# SERDES_10G0 register map
Vendor: Texas Instruments
Registers are 32-bit, access per field, reset 0x0 unless marked. A register's access mark holds for its fields unless they carry their own. Offsets are as the file gives them; [hi:lo] are bit positions; {n}, {i} and the like mark numbered series.

## SERDES_10G0 (part 5 of 8)
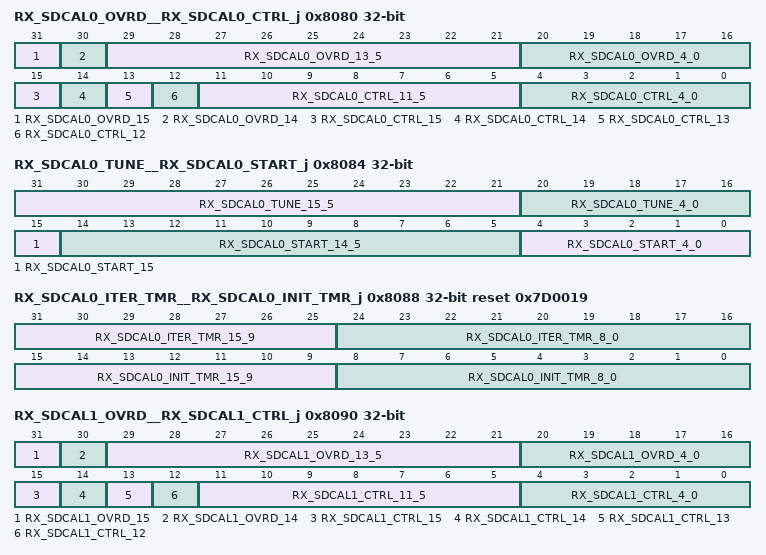
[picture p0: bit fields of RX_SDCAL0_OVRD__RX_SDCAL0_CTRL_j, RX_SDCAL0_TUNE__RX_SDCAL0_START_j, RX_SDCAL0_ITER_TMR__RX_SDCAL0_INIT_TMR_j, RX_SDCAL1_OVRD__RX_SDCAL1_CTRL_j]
0x8080 RX_SDCAL0_OVRD__RX_SDCAL0_CTRL_j — Signal detect calibration 0 control register Offset = 8080h + (j * 400h); where j = 0h to 3h
  [31] RX_SDCAL0_OVRD_15 rw — Calibration code override enable: Activation (1'b1) of this register bit allows the codes determined during the automatic calibration process to be overridden.
  [30] RX_SDCAL0_OVRD_14 rw — Analog calibration enable override: Activation (1'b1) of this register bit will force the analog calibration circuits to be enabled by activating the rxda_sd_cal_0_en enable and the rxda_sd_cal_0_clk clock.
  [29:21] RX_SDCAL0_OVRD_13_5 ro — Reserved
  [20:16] RX_SDCAL0_OVRD_4_0 rw — Calibration code override value: These bits are used to override the calibration code determined during the automatic calibration process.
  [15] RX_SDCAL0_CTRL_15 rw — Start calibration: Activating (1'b1) this bit will start the calibration process.
  [14] RX_SDCAL0_CTRL_14 ro — Calibration process done: This bit will be set to 1'b1 when the calibration process is complete.
  [13] RX_SDCAL0_CTRL_13 ro — No analog calibration response : This signal indicates that the calibration function has gone through the entire calibration process, reached the final calibration value, and the analog has not responded indicating that a valid calibration value has been reached.
  [12] RX_SDCAL0_CTRL_12 ro — Current analog comparator response: This is the current state of the analog comparator response signal (rxda_sd_cal_0_comp).
  [11:5] RX_SDCAL0_CTRL_11_5 ro — Reserved
  [4:0] RX_SDCAL0_CTRL_4_0 ro — Calibration code: This is the calibration code that was determined by the calibration process.
0x8084 RX_SDCAL0_TUNE__RX_SDCAL0_START_j — Signal detect calibration 0 start register Offset = 8084h + (j * 400h); where j = 0h to 3h
  [31:21] RX_SDCAL0_TUNE_15_5 ro — Reserved
  [20:16] RX_SDCAL0_TUNE_4_0 rw — Calibration tune value: The value of this field is added to the automatically calibrated code, or the override code if override is enabled.
  [15] RX_SDCAL0_START_15 rw — Calibration direction: This controls the direction that the automatic calibration process steps the calibration codes in.
  [14:5] RX_SDCAL0_START_14_5 ro — Reserved
  [4:0] RX_SDCAL0_START_4_0 rw — Start calibration code: This is the calibration code that the calibration process starts with when automatic calibration is run.
0x8088 RX_SDCAL0_ITER_TMR__RX_SDCAL0_INIT_TMR_j reset 0x7D0019 — Signal detect calibration 0 initialization timer register Offset = 8088h + (j * 400h); where j = 0h to 3h
  [31:25] RX_SDCAL0_ITER_TMR_15_9 ro — Reserved
  [24:16] RX_SDCAL0_ITER_TMR_8_0 rw — Iteration wait timer value: This is the number of cmn_ref_clk clocks to wait between when a value is placed on the calibration code signals going to the analog, and when the comparator value coming from the analog circuits can be checked.
  [15:9] RX_SDCAL0_INIT_TMR_15_9 ro — Reserved
  [8:0] RX_SDCAL0_INIT_TMR_8_0 rw — Initialization wait timer value: This is the number of cmn_ref_clk clocks to wait between when the analog calibration circuits are enabled, and when the first values are placed on the calibration code signals going to the analog.
0x8090 RX_SDCAL1_OVRD__RX_SDCAL1_CTRL_j — Signal detect calibration 1 control register Offset = 8090h + (j * 400h); where j = 0h to 3h
  [31] RX_SDCAL1_OVRD_15 rw — Calibration code override enable: Activation (1'b1) of this register bit allows the calibration code determined during the automatic calibration process to be overridden.
  [30] RX_SDCAL1_OVRD_14 rw — Analog calibration enable override: Activation (1'b1) of this register bit will force the analog calibration circuits to be enabled by activating the rxda_sd_cal_1_en enable and the rxda_sd_cal_1_clk clock.
  [29:21] RX_SDCAL1_OVRD_13_5 ro — Reserved
  [20:16] RX_SDCAL1_OVRD_4_0 rw — Calibration code override value: These bits are used to override the calibration code determined during the automatic calibration process.
  [15] RX_SDCAL1_CTRL_15 rw — Start calibration: Activating (1'b1) this bit will start the calibration process.
  [14] RX_SDCAL1_CTRL_14 ro — Calibration process done: This bit will be set to 1'b1 when the calibration process is complete.
  [13] RX_SDCAL1_CTRL_13 ro — No analog calibration response : This signal indicates that the calibration function has gone through the entire calibration process, reached the final calibration value, and the analog has not responded indicating that a valid calibration value has been reached.
  [12] RX_SDCAL1_CTRL_12 ro — Current analog comparator response: This is the current state of the analog comparator response signal (rxda_sd_cal_0_comp).
  [11:5] RX_SDCAL1_CTRL_11_5 ro — Reserved
  [4:0] RX_SDCAL1_CTRL_4_0 ro — Calibration code: This is the calibration code that was determined by the calibration process.
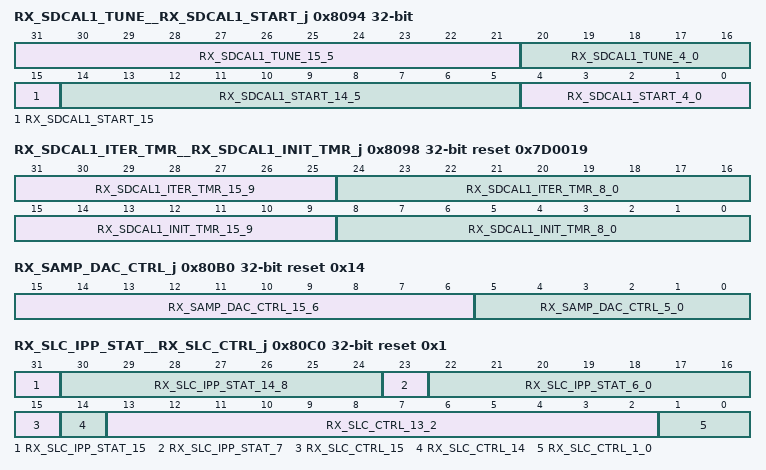
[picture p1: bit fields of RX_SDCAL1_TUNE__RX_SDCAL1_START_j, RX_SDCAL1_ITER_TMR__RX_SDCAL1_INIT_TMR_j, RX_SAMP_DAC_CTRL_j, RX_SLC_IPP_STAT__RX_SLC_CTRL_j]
0x8094 RX_SDCAL1_TUNE__RX_SDCAL1_START_j — Signal detect calibration 1 start register Offset = 8094h + (j * 400h); where j = 0h to 3h
  [31:21] RX_SDCAL1_TUNE_15_5 ro — Reserved
  [20:16] RX_SDCAL1_TUNE_4_0 rw — Calibration tune value: The value of this field is added to the automatically calibrated code, or the override code if override is enabled.
  [15] RX_SDCAL1_START_15 rw — Calibration direction: This controls the direction that the automatic calibration process steps the calibration codes in.
  [14:5] RX_SDCAL1_START_14_5 ro — Reserved
  [4:0] RX_SDCAL1_START_4_0 rw — Start calibration code: This is the calibration code that the calibration process starts with when automatic calibration is run.
0x8098 RX_SDCAL1_ITER_TMR__RX_SDCAL1_INIT_TMR_j reset 0x7D0019 — Signal detect calibration 1 initialization timer register Offset = 8098h + (j * 400h); where j = 0h to 3h
  [31:25] RX_SDCAL1_ITER_TMR_15_9 ro — Reserved
  [24:16] RX_SDCAL1_ITER_TMR_8_0 rw — Iteration wait timer value: This is the number of cmn_ref_clk clocks to wait between when a value is placed on the calibration code signals going to the analog, and when the comparator value coming from the analog circuits can be checked.
  [15:9] RX_SDCAL1_INIT_TMR_15_9 ro — Reserved
  [8:0] RX_SDCAL1_INIT_TMR_8_0 rw — Initialization wait timer value: This is the number of cmn_ref_clk clocks to wait between when the analog calibration circuits are enabled, and when the first values are placed on the calibration code signals going to the analog.
0x80B0 RX_SAMP_DAC_CTRL_j reset 0x14 — Sampler error DAC control register Offset = 80B0h + (j * 400h); where j = 0h to 3h
  [15:6] RX_SAMP_DAC_CTRL_15_6 ro — Reserved
  [5:0] RX_SAMP_DAC_CTRL_5_0 rw — Sampler error DAC value: Specifies the input value to the sampler error DAC.
0x80C0 RX_SLC_IPP_STAT__RX_SLC_CTRL_j reset 0x1 — RX sampler latch calibration control register Offset = 80C0h + (j * 400h); where j = 0h to 3h
  [31] RX_SLC_IPP_STAT_15 ro — Reserved
  [30:24] RX_SLC_IPP_STAT_14_8 ro — I even latch receiver sampler calibration DAC value: This field contains the current value that the RX sampler latch calibration module has calculated to drive to the DAC that controls the offset for the I even latch in the analog sampler component.
  [23] RX_SLC_IPP_STAT_7 ro — Reserved
  [22:16] RX_SLC_IPP_STAT_6_0 ro — I odd latch receiver sampler calibration DAC value: This field contains the current value that the RX sampler latch calibration module has calculated to drive to the DAC that controls the offset for the I odd latch in the analog sampler component.
  [15] RX_SLC_CTRL_15 rw — Start RX sampler latch calibration: Activating (1'b1) this bit will start the RX sampler latch calibration process.
  [14] RX_SLC_CTRL_14 ro — RX sampler latch calibration process done: This bit will be set to 1'b1 when the RX sampler latch calibration process is complete.
  [13:2] RX_SLC_CTRL_13_2 ro — Reserved
  [1:0] RX_SLC_CTRL_1_0 rw — RX sampler latch calibration scaler: This field specifies the scaler value used for the input data accumulator.
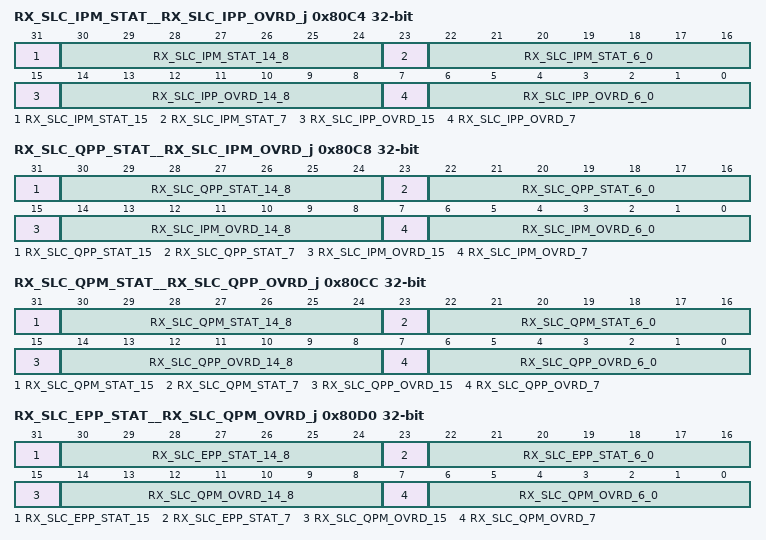
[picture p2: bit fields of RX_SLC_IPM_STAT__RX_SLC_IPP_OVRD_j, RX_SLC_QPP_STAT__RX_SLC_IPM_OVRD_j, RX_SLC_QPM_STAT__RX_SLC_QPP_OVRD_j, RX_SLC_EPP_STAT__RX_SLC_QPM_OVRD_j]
0x80C4 RX_SLC_IPM_STAT__RX_SLC_IPP_OVRD_j — RX sampler latch calibration I predictive positive override register Offset = 80C4h + (j * 400h); where j = 0h to 3h
  [31] RX_SLC_IPM_STAT_15 ro — Reserved
  [30:24] RX_SLC_IPM_STAT_14_8 ro — I even latch receiver sampler calibration DAC value: This field contains the current value that the RX sampler latch calibration module has calculated to drive to the DAC that controls the offset for the I even latch in the analog sampler component.
  [23] RX_SLC_IPM_STAT_7 ro — Reserved
  [22:16] RX_SLC_IPM_STAT_6_0 ro — I odd latch receiver sampler calibration DAC value: This field contains the current value that the RX sampler latch calibration module has calculated to drive to the DAC that controls the offset for the I odd latch in the analog sampler component.
  [15] RX_SLC_IPP_OVRD_15 rw — I even latch receiver sampler calibration DAC override enable: When this bit is active (1'b1), the value in the I even latch receiver sampler calibration DAC override value field of this register will override the calibrated value for the I even sampler latch.
  [14:8] RX_SLC_IPP_OVRD_14_8 rw — I even latch receiver sampler calibration DAC override value: This field contains the value that can be used to override the calibrated value for the I even sampler latch.
  [7] RX_SLC_IPP_OVRD_7 rw — I odd latch receiver sampler calibration DAC override enable: When this bit is active (1'b1), the value in the I odd latch receiver sampler calibration DAC override value field of this register will override the calibrated value for the I odd sampler latch.
  [6:0] RX_SLC_IPP_OVRD_6_0 rw — I odd latch receiver sampler calibration DAC override value: This field contains the value that can be used to override the calibrated value for the I odd sampler latch.
0x80C8 RX_SLC_QPP_STAT__RX_SLC_IPM_OVRD_j — RX sampler latch calibration I predictive negative override register Offset = 80C8h + (j * 400h); where j = 0h to 3h
  [31] RX_SLC_QPP_STAT_15 ro — Reserved
  [30:24] RX_SLC_QPP_STAT_14_8 ro — Q even latch receiver sampler calibration DAC value: This field contains the current value that the RX sampler latch calibration module has calculated to drive to the DAC that controls the offset for the Q even latch in the analog sampler component.
  [23] RX_SLC_QPP_STAT_7 ro — Reserved
  [22:16] RX_SLC_QPP_STAT_6_0 ro — Q odd latch receiver sampler calibration DAC value: This field contains the current value that the RX sampler latch calibration module has calculated to drive to the DAC that controls the offset for the Q odd latch in the analog sampler component.
  [15] RX_SLC_IPM_OVRD_15 rw — I eve latch receiver sampler calibration DAC override enable: When this bit is active (1'b1), the value in the I even latch receiver sampler calibration DAC override value field of this register will override the calibrated value for the I even sampler latch.
  [14:8] RX_SLC_IPM_OVRD_14_8 rw — I even latch receiver sampler calibration DAC override value: This field contains the value that can be used to override the calibrated value for the I even sampler latch.
  [7] RX_SLC_IPM_OVRD_7 rw — I odd latch receiver sampler calibration DAC override enable: When this bit is active (1'b1), the value in the I odd latch receiver sampler calibration DAC override value field of this register will override the calibrated value for the I odd sampler latch.
  [6:0] RX_SLC_IPM_OVRD_6_0 rw — I odd latch receiver sampler calibration DAC override value: This field contains the value that can be used to override the calibrated value for the I odd sampler latch.
0x80CC RX_SLC_QPM_STAT__RX_SLC_QPP_OVRD_j — RX sampler latch calibration Q predictive positive override register Offset = 80CCh + (j * 400h); where j = 0h to 3h
  [31] RX_SLC_QPM_STAT_15 ro — Reserved
  [30:24] RX_SLC_QPM_STAT_14_8 ro — Q even latch receiver sampler calibration DAC value: This field contains the current value that the RX sampler latch calibration module has calculated to drive to the DAC that controls the offset for the Q even latch in the analog sampler component.
  [23] RX_SLC_QPM_STAT_7 ro — Reserved
  [22:16] RX_SLC_QPM_STAT_6_0 ro — Q odd latch receiver sampler calibration DAC value: This field contains the current value that the RX sampler latch calibration module has calculated to drive to the DAC that controls the offset for the Q odd latch in the analog sampler component.
  [15] RX_SLC_QPP_OVRD_15 rw — Q even latch receiver sampler calibration DAC override enable: When this bit is active (1'b1), the value in the Q even latch receiver sampler calibration DAC override value field of this register will override the calibrated value for the Q even sampler latch.
  [14:8] RX_SLC_QPP_OVRD_14_8 rw — Q even latch receiver sampler calibration DAC override value: This field contains the value that can be used to override the calibrated value for the Q even sampler latch.
  [7] RX_SLC_QPP_OVRD_7 rw — Q odd latch receiver sampler calibration DAC override enable: When this bit is active (1'b1), the value in the Q odd latch receiver sampler calibration DAC override value field of this register will override the calibrated value for the Q odd sampler latch.
  [6:0] RX_SLC_QPP_OVRD_6_0 rw — Q odd latch receiver sampler calibration DAC override value: This field contains the value that can be used to override the calibrated value for the Q odd sampler latch.
0x80D0 RX_SLC_EPP_STAT__RX_SLC_QPM_OVRD_j — RX sampler latch calibration Q predictive negative override register Offset = 80D0h + (j * 400h); where j = 0h to 3h
  [31] RX_SLC_EPP_STAT_15 ro — Reserved
  [30:24] RX_SLC_EPP_STAT_14_8 ro — e even latch receiver sampler calibration DAC value: This field contains the current value that the RX sampler latch calibration module has calculated to drive to the DAC that controls the offset for the e even latch in the analog sampler component.
  [23] RX_SLC_EPP_STAT_7 ro — Reserved
  [22:16] RX_SLC_EPP_STAT_6_0 ro — e odd latch receiver sampler calibration DAC value: This field contains the current value that the RX sampler latch calibration module has calculated to drive to the DAC that controls the offset for the e odd latch in the analog sampler component.
  [15] RX_SLC_QPM_OVRD_15 rw — Q even latch receiver sampler calibration DAC override enable: When this bit is active (1'b1), the value in the Q even latch receiver sampler calibration DAC override value field of this register will override the calibrated value for the Q even sampler latch.
  [14:8] RX_SLC_QPM_OVRD_14_8 rw — Q even latch receiver sampler calibration DAC override value: This field contains the value that can be used to override the calibrated value for the Q even sampler latch.
  [7] RX_SLC_QPM_OVRD_7 rw — Q odd latch receiver sampler calibration DAC override enable: When this bit is active (1'b1), the value in the Q odd latch receiver sampler calibration DAC override value field of this register will override the calibrated value for the Q odd sampler latch.
  [6:0] RX_SLC_QPM_OVRD_6_0 rw — Q odd latch receiver sampler calibration DAC override value: This field contains the value that can be used to override the calibrated value for the Q odd sampler latch.
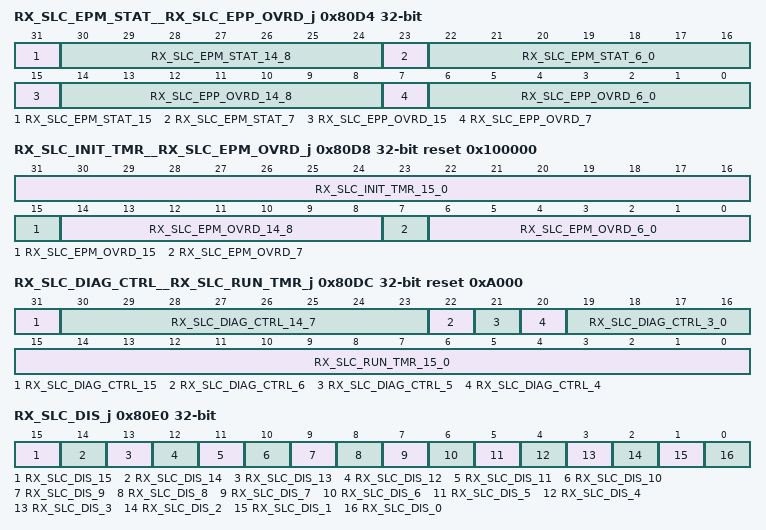
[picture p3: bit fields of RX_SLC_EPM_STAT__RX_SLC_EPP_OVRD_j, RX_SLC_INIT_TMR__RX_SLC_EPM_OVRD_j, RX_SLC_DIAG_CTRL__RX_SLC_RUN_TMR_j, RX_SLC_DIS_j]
0x80D4 RX_SLC_EPM_STAT__RX_SLC_EPP_OVRD_j — RX sampler latch calibration e predictive positive override register Offset = 80D4h + (j * 400h); where j = 0h to 3h
  [31] RX_SLC_EPM_STAT_15 ro — Reserved
  [30:24] RX_SLC_EPM_STAT_14_8 ro — e even latch receiver sampler calibration DAC value: This field contains the current value that the RX sampler latch calibration module has calculated to drive to the DAC that controls the offset for the e even latch in the analog sampler component.
  [23] RX_SLC_EPM_STAT_7 ro — Reserved
  [22:16] RX_SLC_EPM_STAT_6_0 ro — e odd latch receiver sampler calibration DAC value: This field contains the current value that the RX sampler latch calibration module has calculated to drive to the DAC that controls the offset for the e odd latch in the analog sampler component.
  [15] RX_SLC_EPP_OVRD_15 rw — e even latch receiver sampler calibration DAC override enable: When this bit is active (1'b1), the value in the e even latch receiver sampler calibration DAC override value field of this register will override the calibrated value for the e even sampler latch.
  [14:8] RX_SLC_EPP_OVRD_14_8 rw — e even latch receiver sampler calibration DAC override value: This field contains the value that can be used to override the calibrated value for the e even sampler latch.
  [7] RX_SLC_EPP_OVRD_7 rw — e odd latch receiver sampler calibration DAC override enable: When this bit is active (1'b1), the value in the e odd latch receiver sampler calibration DAC override value field of this register will override the calibrated value for the e odd sampler latch.
  [6:0] RX_SLC_EPP_OVRD_6_0 rw — e odd latch receiver sampler calibration DAC override value: This field contains the value that can be used to override the calibrated value for the e odd sampler latch.
0x80D8 RX_SLC_INIT_TMR__RX_SLC_EPM_OVRD_j rw reset 0x100000 — RX sampler latch calibration e predictive negative override register Offset = 80D8h + (j * 400h); where j = 0h to 3h
  [31:16] RX_SLC_INIT_TMR_15_0 — RX sampler latch calibration initialization timer value : This is the value that will be used for the RX sampler latch calibration initialization timer, which controls the time the rxda_sampler_latch_cal_en is held active prior to the individual calibration processes being kicked off.
  [15] RX_SLC_EPM_OVRD_15 — e even latch receiver sampler calibration DAC override enable: When this bit is active (1'b1), the value in the e even latch receiver sampler calibration DAC override value field of this register will override the calibrated value for the e even sampler latch.
  [14:8] RX_SLC_EPM_OVRD_14_8 — e even latch receiver sampler calibration DAC override value: This field contains the value that can be used to override the calibrated value for the e even sampler latch.
  [7] RX_SLC_EPM_OVRD_7 — e odd latch receiver sampler calibration DAC override enable: When this bit is active (1'b1), the value in the e odd latch receiver sampler calibration DAC override value field of this register will override the calibrated value for the e odd sampler latch.
  [6:0] RX_SLC_EPM_OVRD_6_0 — e odd latch receiver sampler calibration DAC override value: This field contains the value that can be used to override the calibrated value for the e odd sampler latch.
0x80DC RX_SLC_DIAG_CTRL__RX_SLC_RUN_TMR_j reset 0xA000 — RX sampler latch calibration run timer value register Offset = 80DCh + (j * 400h); where j = 0h to 3h
  [31] RX_SLC_DIAG_CTRL_15 rw — Diagnostic control enable : This bit enables the selected RX sampler latch calibration data sub module for diagnostic purposes.
  [30:23] RX_SLC_DIAG_CTRL_14_7 ro — Reserved
  [22] RX_SLC_DIAG_CTRL_6 rw — Voter override neg : When enabled using the voter override enable bit in this register, writing a 1'b1 in this register bit will force the voter in the selected RX sampler latch calibration data sub module to activate the voter neg signal for a single clock cycle.
  [21] RX_SLC_DIAG_CTRL_5 rw — Voter override pos : When enabled using the voter override enable bit in this register, writing a 1'b1 in this register bit will force the voter in the selected RX sampler latch calibration data sub module to activate the voter pos signal for a single clock cycle.
  [20] RX_SLC_DIAG_CTRL_4 rw — Voter override enable : Setting this bit to a 1'b1 will enable the voter override function in the selected RX sampler latch calibration data sub module.
  [19:16] RX_SLC_DIAG_CTRL_3_0 rw — Diagnostic control override select : Selects the RX sampler latch calibration data sub module to enable for diagnostic and verification purposes.
  [15:0] RX_SLC_RUN_TMR_15_0 rw — RX sampler latch calibration run timer value : This is the value that will be used for the RX sampler latch calibration run timer, which controls the run time for each calibration process.
0x80E0 RX_SLC_DIS_j — RX sampler latch calibration disable register Offset = 80E0h + (j * 400h); where j = 0h to 3h
  [15] RX_SLC_DIS_15 ro — Reserved
  [14] RX_SLC_DIS_14 rw — e even negative coefficient disable : Writing a 1'b1 to this bit will disable auto calibration for the e even negative coefficient RX sampler latch calibration data sub module.
  [13] RX_SLC_DIS_13 rw — q even negative coefficient disable : Writing a 1'b1 to this bit will disable auto calibration for the q even negative coefficient RX sampler latch calibration data sub module.
  [12] RX_SLC_DIS_12 rw — i even negative coefficient disable : Writing a 1'b1 to this bit will disable auto calibration for the i even negative coefficient RX sampler latch calibration data sub module.
  [11] RX_SLC_DIS_11 ro — Reserved
  [10] RX_SLC_DIS_10 rw — e even positive coefficient disable : Writing a 1'b1 to this bit will disable auto calibration for the e even positive coefficient RX sampler latch calibration data sub module.
  [9] RX_SLC_DIS_9 rw — q even positive coefficient disable : Writing a 1'b1 to this bit will disable auto calibration for the q even positive coefficient RX sampler latch calibration data sub module.
  [8] RX_SLC_DIS_8 rw — i even positive coefficient disable : Writing a 1'b1 to this bit will disable auto calibration for the i even positive coefficient RX sampler latch calibration data sub module.
  [7] RX_SLC_DIS_7 ro — Reserved
  [6] RX_SLC_DIS_6 rw — e odd negative coefficient disable : Writing a 1'b1 to this bit will disable auto calibration for the e odd negative coefficient RX sampler latch calibration data sub module.
  [5] RX_SLC_DIS_5 rw — q odd negative coefficient disable : Writing a 1'b1 to this bit will disable auto calibration for the q odd negative coefficient RX sampler latch calibration data sub module.
  [4] RX_SLC_DIS_4 rw — i odd negative coefficient disable : Writing a 1'b1 to this bit will disable auto calibration for the i odd negative coefficient RX sampler latch calibration data sub module.
  [3] RX_SLC_DIS_3 ro — Reserved
  [2] RX_SLC_DIS_2 rw — e odd positive coefficient disable : Writing a 1'b1 to this bit will disable auto calibration for the e odd positive coefficient RX sampler latch calibration data sub module.
  [1] RX_SLC_DIS_1 rw — q odd positive coefficient disable : Writing a 1'b1 to this bit will disable auto calibration for the q odd positive coefficient RX sampler latch calibration data sub module.
  [0] RX_SLC_DIS_0 rw — i odd positive coefficient disable : Writing a 1'b1 to this bit will disable auto calibration for the i odd positive coefficient RX sampler latch calibration data sub module.
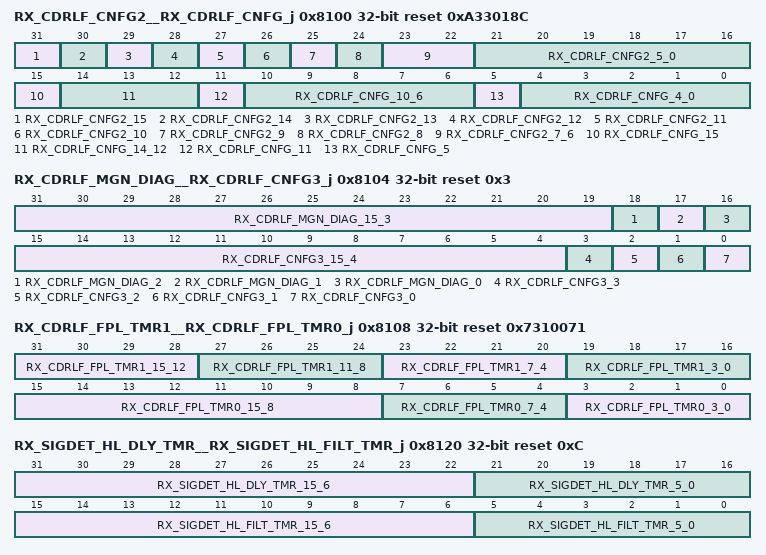
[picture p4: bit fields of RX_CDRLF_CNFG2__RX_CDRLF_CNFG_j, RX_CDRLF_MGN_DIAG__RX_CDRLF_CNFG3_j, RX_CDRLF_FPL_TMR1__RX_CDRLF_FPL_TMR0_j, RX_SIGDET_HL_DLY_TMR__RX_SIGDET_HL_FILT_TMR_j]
0x8100 RX_CDRLF_CNFG2__RX_CDRLF_CNFG_j reset 0xA33018C — CDRLF configuration register Offset = 8100h + (j * 400h); where j = 0h to 3h
  [31] RX_CDRLF_CNFG2_15 ro — Reserved
  [30] RX_CDRLF_CNFG2_14 rw — CDRLF second order loop integrator max clear enable: This signal enables the function in the CDRLF where the second order loop integrator is cleared when it reaches the maximum value.
  [29] RX_CDRLF_CNFG2_13 ro — CDRLF fast phase lock locked detected: This register bit is the current status of the fphl_locked pin on the CDRLF, and indicates the fast phase lock process is complete.
  [28] RX_CDRLF_CNFG2_12 rw — CDRLF fast phase lock diagnostic enable: This register bit can control the fphl_start pin on the CDRLF.
  [27] RX_CDRLF_CNFG2_11 rw — CDRLF fast phase lock enabled by signal detect: When active, signal detect will control the fphl_start pin on the CDRLF.
  [26] RX_CDRLF_CNFG2_10 rw — CDRLF reset on CDRLF PM Accumulator Max: Activating (1'b1) this bit will force the CDRLF to be reset when the PM accumulator in the CDRLF reaches is maximum absolute value (the largest positive or negative value).
  [25] RX_CDRLF_CNFG2_9 rw — CDRLF freeze on electrical idle detect: Activating (1'b1) this bit will force the CDRLF to be freeze in its current state when the receiver signal detect detects an electrical idle.
  [24] RX_CDRLF_CNFG2_8 rw — CDRLF reset on electrical idle detect: Activating (1'b1) this bit will force the CDRLF to be reset when the receiver signal detect detects an electrical idle.
  [23:22] RX_CDRLF_CNFG2_7_6 ro — Reserved
  [21:16] RX_CDRLF_CNFG2_5_0 rw — CDRLF second order loop integrator threshold : This value is the maximum magnitude the CDRLF second order loop integrator will be allowed to go to.
  [15] RX_CDRLF_CNFG_15 rw — CDLRF reset hold: When active (1'b1), the CDRLF will be held in reset beyond the time that it would normally be released by its asynchronous release signals.
  [14:12] RX_CDRLF_CNFG_14_12 rw — CDRLF diagnostic mode control: This field controls the information driven on the rx_pi_val_ln_{15:0}[7:0] signal, when in diagnostics mode.
  [11] RX_CDRLF_CNFG_11 rw — CDRLF second order loop disable: Activating (1'b1) this bit will disable the CDRLF second order loop.
  [10:6] RX_CDRLF_CNFG_10_6 rw — CDRLF second order loop sigma delta update rate: This is the value that is added to or subtracted from the second order loop accumulator register when the serial data sample clock is detected as being out of phase with the serial data on a given parallel data word cycle.
  [5] RX_CDRLF_CNFG_5 rw — CDRLF first order loop disable: Activating (1'b1) this bit will disable the CDRLF first order loop.
  [4:0] RX_CDRLF_CNFG_4_0 rw — CDRLF first order loop sigma delta update rate: This is the value that is added to or subtracted from the first order loop accumulator register when the serial data sample clock is detected as being out of phase with the serial data on a given parallel data word cycle.
0x8104 RX_CDRLF_MGN_DIAG__RX_CDRLF_CNFG3_j reset 0x3 — CDRLF configuration register 3 Offset = 8104h + (j * 400h); where j = 0h to 3h
  [31:19] RX_CDRLF_MGN_DIAG_15_3 ro — Reserved
  [18] RX_CDRLF_MGN_DIAG_2 wo — CDRLF PI override down : When the CDRLF PI override enable function is enabled, writing a 1'b1 to this bit will force a down to be generated in the CDRLF PI interface logic.
  [17] RX_CDRLF_MGN_DIAG_1 wo — CDRLF PI override up : When the CDRLF PI override enable function is enabled, writing a 1'b1 to this bit will force an up to be generated in the CDRLF PI interface logic.
  [16] RX_CDRLF_MGN_DIAG_0 rw — CDRLF PI override enable : Setting this bit to 1'b1 will enable the CDRLF PI override function, which will allow ups and downs to be forced to the CDRLF PI interface logic from the up and down override bits in this register.
  [15:4] RX_CDRLF_CNFG3_15_4 ro — Reserved
  [3] RX_CDRLF_CNFG3_3 rw — CDRLF data filter enable standard mode 3 : Enables the filter function for the data that feeds into the CDRLF from the deserializer, using the rxda_cdrlf_data_filter_en_n signal, when xcvr_standard_mode is set to 2'b11.
  [2] RX_CDRLF_CNFG3_2 rw — CDRLF data filter enable standard mode 2 : Enables the filter function for the data that feeds into the CDRLF from the deserializer, using the rxda_cdrlf_data_filter_en_n signal, when xcvr_standard_mode is set to 2'b10.
  [1] RX_CDRLF_CNFG3_1 rw — CDRLF data filter enable standard mode 1 : Enables the filter function for the data that feeds into the CDRLF from the deserializer, using the rxda_cdrlf_data_filter_en_n signal, when xcvr_standard_mode is set to 2'b01.
  [0] RX_CDRLF_CNFG3_0 rw — CDRLF data filter enable standard mode 0 : Enables the filter function for the data that feeds into the CDRLF from the deserializer, using the rxda_cdrlf_data_filter_en_n signal, when xcvr_standard_mode is set to 2'b00.
0x8108 RX_CDRLF_FPL_TMR1__RX_CDRLF_FPL_TMR0_j reset 0x7310071 — CDRLF fast phase lock timer value register 0 Offset = 8108h + (j * 400h); where j = 0h to 3h
  [31:28] RX_CDRLF_FPL_TMR1_15_12 ro — Reserved
  [27:24] RX_CDRLF_FPL_TMR1_11_8 rw — Fast phase lock timer trigger 1 state time value : Specifies the number of clock cycles minus 1 that the fast phase lock state machine will remain in the trigger state the first time it is in that state.
  [23:20] RX_CDRLF_FPL_TMR1_7_4 rw — Fast phase lock timer trigger 2 state time value : Specifies the number of clock cycles minus 1 that the fast phase lock state machine will remain in the trigger state the second time it is in that state.
  [19:16] RX_CDRLF_FPL_TMR1_3_0 rw — Fast phase lock timer trigger 3 state time value : Specifies the number of clock cycles minus 1 that the fast phase lock state machine will remain in the trigger state the third time it is in that state.
  [15:8] RX_CDRLF_FPL_TMR0_15_8 ro — Reserved
  [7:4] RX_CDRLF_FPL_TMR0_7_4 rw — Fast phase lock timer accumulate state time value : Specifies the number of clock cycles minus 1 that the fast phase lock state machine will remain in the accumulate state.
  [3:0] RX_CDRLF_FPL_TMR0_3_0 rw — Fast phase lock timer delay state time value : Specifies the number of clock cycles minus 1 that the fast phase lock state machine will remain in the delay state.
0x8120 RX_SIGDET_HL_DLY_TMR__RX_SIGDET_HL_FILT_TMR_j reset 0xC — Receiver signal detect filter high to low filter timer register Offset = 8120h + (j * 400h); where j = 0h to 3h
  [31:22] RX_SIGDET_HL_DLY_TMR_15_6 ro — Reserved
  [21:16] RX_SIGDET_HL_DLY_TMR_5_0 rw — Signal detect filter high to low delay timer value: This is the value loaded into the delay timer in the signal detect high to low filter circuit.
  [15:6] RX_SIGDET_HL_FILT_TMR_15_6 ro — Reserved
  [5:0] RX_SIGDET_HL_FILT_TMR_5_0 rw — Signal detect filter high to low filter timer value: This is the value loaded into the filter timer in the signal detect high to low filter circuit.
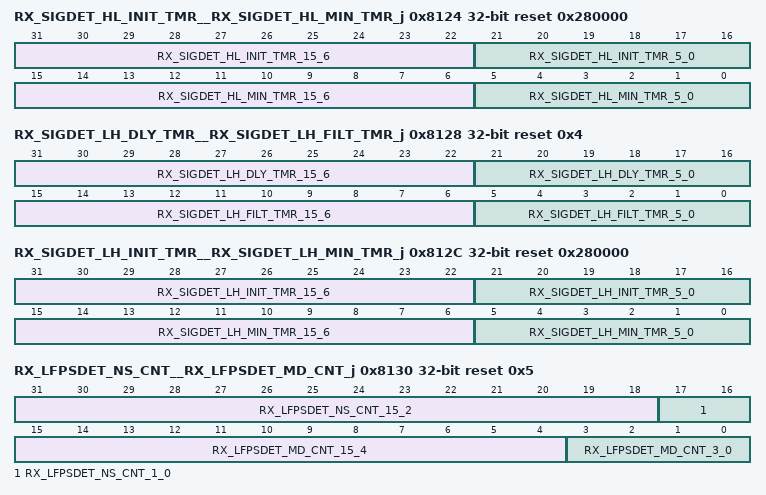
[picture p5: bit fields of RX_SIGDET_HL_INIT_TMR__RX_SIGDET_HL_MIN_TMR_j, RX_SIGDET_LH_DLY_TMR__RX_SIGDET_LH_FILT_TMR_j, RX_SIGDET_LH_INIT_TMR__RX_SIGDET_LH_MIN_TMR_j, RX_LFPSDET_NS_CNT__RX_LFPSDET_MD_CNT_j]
0x8124 RX_SIGDET_HL_INIT_TMR__RX_SIGDET_HL_MIN_TMR_j reset 0x280000 — Receiver signal detect filter high to low min timer register Offset = 8124h + (j * 400h); where j = 0h to 3h
  [31:22] RX_SIGDET_HL_INIT_TMR_15_6 ro — Reserved
  [21:16] RX_SIGDET_HL_INIT_TMR_5_0 rw — Signal detect init timer value: This is the value loaded into the initialization timer in the signal detect filter high to low filter circuit.
  [15:6] RX_SIGDET_HL_MIN_TMR_15_6 ro — Reserved
  [5:0] RX_SIGDET_HL_MIN_TMR_5_0 rw — Signal detect filter high to low min timer value: This is the value loaded into the min timer in the signal detect high to low filter circuit.
0x8128 RX_SIGDET_LH_DLY_TMR__RX_SIGDET_LH_FILT_TMR_j reset 0x4 — Receiver signal detect filter low to high filter timer register Offset = 8128h + (j * 400h); where j = 0h to 3h
  [31:22] RX_SIGDET_LH_DLY_TMR_15_6 ro — Reserved
  [21:16] RX_SIGDET_LH_DLY_TMR_5_0 rw — Signal detect filter low to high min timer value: This is the value loaded into the min timer in the signal detect low to high filter circuit.
  [15:6] RX_SIGDET_LH_FILT_TMR_15_6 ro — Reserved
  [5:0] RX_SIGDET_LH_FILT_TMR_5_0 rw — Signal detect filter low to high filter timer value: This is the value loaded into the filter timer in the signal detect low to high filter circuit.
0x812C RX_SIGDET_LH_INIT_TMR__RX_SIGDET_LH_MIN_TMR_j reset 0x280000 — Receiver signal detect filter low to high min timer register Offset = 812Ch + (j * 400h); where j = 0h to 3h
  [31:22] RX_SIGDET_LH_INIT_TMR_15_6 ro — Reserved
  [21:16] RX_SIGDET_LH_INIT_TMR_5_0 rw — Signal detect init timer value: This is the value loaded into the initialization timer in the signal detect filter high to low filter circuit.
  [15:6] RX_SIGDET_LH_MIN_TMR_15_6 ro — Reserved
  [5:0] RX_SIGDET_LH_MIN_TMR_5_0 rw — Signal detect filter high to low min timer value: This is the value loaded into the min timer in the signal detect high to low filter circuit.
0x8130 RX_LFPSDET_NS_CNT__RX_LFPSDET_MD_CNT_j reset 0x5 — Receiver LFPS detect minimum pulse distance counter register Offset = 8130h + (j * 400h); where j = 0h to 3h
  [31:18] RX_LFPSDET_NS_CNT_15_2 ro — Reserved
  [17:16] RX_LFPSDET_NS_CNT_1_0 rw — No signal counter value (NS): Specifies the number of clock cycles where pulse_high and pulse_low are inactive before declaring no signal.
  [15:4] RX_LFPSDET_MD_CNT_15_4 ro — Reserved
  [3:0] RX_LFPSDET_MD_CNT_3_0 rw — Minimum pulse distance counter value (MD): Specifies the minimum pulse distance for a valid LFPS sequence.
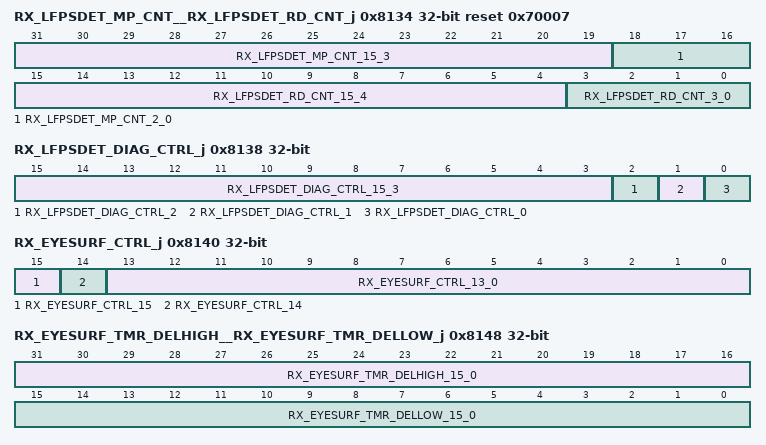
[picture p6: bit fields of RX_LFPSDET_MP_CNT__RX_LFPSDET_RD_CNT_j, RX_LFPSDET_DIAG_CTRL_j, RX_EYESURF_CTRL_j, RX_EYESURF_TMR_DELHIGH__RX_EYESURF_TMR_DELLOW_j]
0x8134 RX_LFPSDET_MP_CNT__RX_LFPSDET_RD_CNT_j reset 0x70007 — Receiver LFPS detect ramp down counter register Offset = 8134h + (j * 400h); where j = 0h to 3h
  [31:19] RX_LFPSDET_MP_CNT_15_3 ro — Reserved
  [18:16] RX_LFPSDET_MP_CNT_2_0 rw — Minimum pulse duration (MP): Specifies the minimum number of clock cycles required for a given LFPS pulse to be driven active to be considered part of a valid LFPS burst.
  [15:4] RX_LFPSDET_RD_CNT_15_4 ro — Reserved
  [3:0] RX_LFPSDET_RD_CNT_3_0 rw — Ramp down counter value (RD): Species the number of clock cycles that are used in the LFPS detect ramp down process.
0x8138 RX_LFPSDET_DIAG_CTRL_j — Receiver LFPS detect diagnostic control register Offset = 8138h + (j * 400h); where j = 0h to 3h
  [15:3] RX_LFPSDET_DIAG_CTRL_15_3 ro — Reserved
  [2] RX_LFPSDET_DIAG_CTRL_2 rw — Disable pulse none MD check: When active (1'b1), the check that tests if pulse_none is driven inactive while the MD check is being performed will be disabled.
  [1] RX_LFPSDET_DIAG_CTRL_1 rw — LFPS detect override enable: When active (1'b1), the LFPS detect override bit in this register will drive the LFPS detect output directly.
  [0] RX_LFPSDET_DIAG_CTRL_0 rw — LFPS detect override: When enabled by the LFPS detect override enable bit in this register, this bit will drive the LFPS detect output directly.
0x8140 RX_EYESURF_CTRL_j — Eye surf control register Offset = 8140h + (j * 400h); where j = 0h to 3h
  [15] RX_EYESURF_CTRL_15 rw — Eye surf run: Setting this bit to 1'b1 will initiate the eye surf process.
  [14] RX_EYESURF_CTRL_14 ro — Eye surf done: When this bit is set to 1'b1, the eye surf process has completed.
  [13:0] RX_EYESURF_CTRL_13_0 ro — Reserved
0x8148 RX_EYESURF_TMR_DELHIGH__RX_EYESURF_TMR_DELLOW_j rw — Eye surf timer delay low register Offset = 8148h + (j * 400h); where j = 0h to 3h
  [31:16] RX_EYESURF_TMR_DELHIGH_15_0 — Most significant 16 bits of the delay time: The delay time specifies the number of clock cycles to wait between when a coordinate test point is set, and when to start testing the i and e data.
  [15:0] RX_EYESURF_TMR_DELLOW_15_0 — Least significant 16 bits of the delay time: The delay time specifies the number of clock cycles to wait between when a coordinate test point is set, and when to start testing the i and e data.
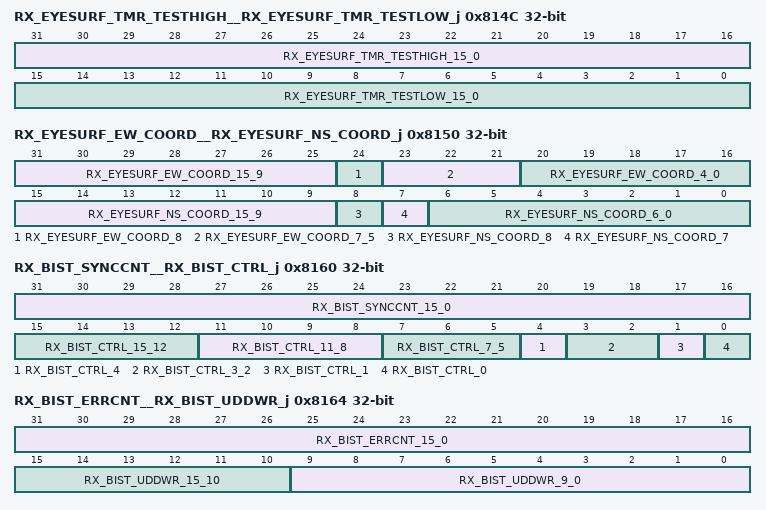
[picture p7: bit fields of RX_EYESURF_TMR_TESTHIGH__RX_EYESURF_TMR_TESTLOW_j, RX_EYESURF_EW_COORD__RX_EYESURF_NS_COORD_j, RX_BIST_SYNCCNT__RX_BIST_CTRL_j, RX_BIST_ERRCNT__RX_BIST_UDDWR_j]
0x814C RX_EYESURF_TMR_TESTHIGH__RX_EYESURF_TMR_TESTLOW_j rw — Eye surf timer test low register Offset = 814Ch + (j * 400h); where j = 0h to 3h
  [31:16] RX_EYESURF_TMR_TESTHIGH_15_0 — Most significant 16 bits of the test time: The test time specifies the number of clock cycles to test the i and e data at a given coordinate test point.
  [15:0] RX_EYESURF_TMR_TESTLOW_15_0 — Least significant 16 bits of the test time: The test time specifies the number of clock cycles to test the i and e data at a given coordinate test point.
0x8150 RX_EYESURF_EW_COORD__RX_EYESURF_NS_COORD_j — Eye surf north south test point coordinate register Offset = 8150h + (j * 400h); where j = 0h to 3h
  [31:25] RX_EYESURF_EW_COORD_15_9 ro — Reserved
  [24] RX_EYESURF_EW_COORD_8 rw — Test point coordinate east west direction : Indicates whether the desired test point is in the
  [23:21] RX_EYESURF_EW_COORD_7_5 ro — Reserved
  [20:16] RX_EYESURF_EW_COORD_4_0 rw — Test point coordinate east west offset : Indicates how many steps in the east or west
  [15:9] RX_EYESURF_NS_COORD_15_9 ro — Reserved
  [8] RX_EYESURF_NS_COORD_8 rw — Test point coordinate north south direction : Indicates whether the desired test point is in the north or the south direction relative to the origin.
  [7] RX_EYESURF_NS_COORD_7 ro — Reserved
  [6:0] RX_EYESURF_NS_COORD_6_0 rw — Test point coordinate north south offset : Indicates how many steps in the north or south direction the desired test point is relative to the origin.
0x8154 RX_EYESURF_ERRCNT_j ro — Eye surf bit error count register Offset = 8154h + (j * 400h); where j = 0h to 3h
  [15:0] RX_EYESURF_ERRCNT_15_0 — Test point bit error count : The total number of bit errors that were detected for a given run of the eye surf function.
0x8160 RX_BIST_SYNCCNT__RX_BIST_CTRL_j — Receiver BIST control register Offset = 8160h + (j * 400h); where j = 0h to 3h
  [31:16] RX_BIST_SYNCCNT_15_0 rw — Receiver BIST sync count: This field controls the value of the RX BIST sync count.
  [15:12] RX_BIST_CTRL_15_12 ro — Reserved
  [11:8] RX_BIST_CTRL_11_8 rw — Receiver BIST mode: Controls which mode the BIST will operate in.
  [7:5] RX_BIST_CTRL_7_5 ro — Reserved
  [4] RX_BIST_CTRL_4 rw — Receiver BIST error reset: Writing this bit is set to a 1'b1 will hold the error indicators in the receive BIST logic in reset.
  [3:2] RX_BIST_CTRL_3_2 ro — Reserved
  [1] RX_BIST_CTRL_1 wo — Receiver BIST user defined data FIFO clear: Writing a 1'b1 to this bit will clear the receiver BIST user defined data FIFO.
  [0] RX_BIST_CTRL_0 rw — Receiver BIST enable: This bit enables the receiver BIST function.
0x8164 RX_BIST_ERRCNT__RX_BIST_UDDWR_j — Receiver BIST user defined data write register Offset = 8164h + (j * 400h); where j = 0h to 3h
  [31:16] RX_BIST_ERRCNT_15_0 ro — Receiver BIST error count: Indicates the number of BIST errors that have been observed by the receive BIST logic, since the last time the BIST error indicator logic was reset or restarted.
  [15:10] RX_BIST_UDDWR_15_10 ro — Reserved
  [9:0] RX_BIST_UDDWR_9_0 wo — Receiver BIST user defined data: Writing a data word to this field will result in that data word being placed in the next available position in the receiver BIST user defined data FIFO.
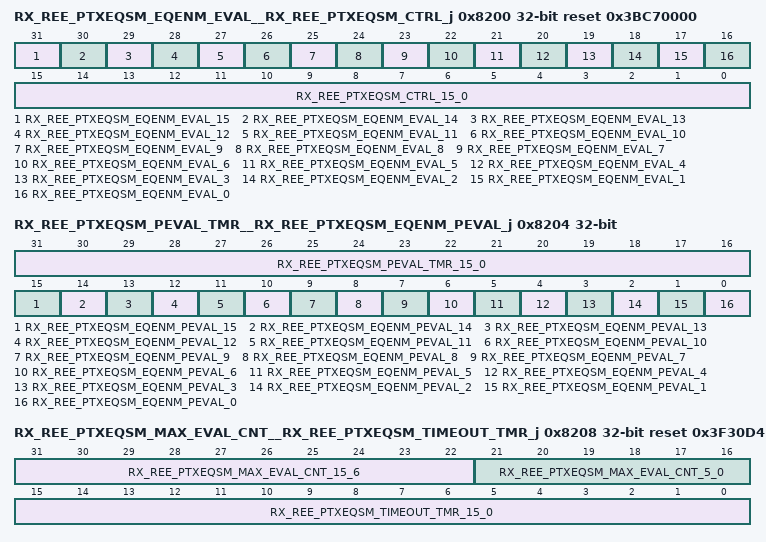
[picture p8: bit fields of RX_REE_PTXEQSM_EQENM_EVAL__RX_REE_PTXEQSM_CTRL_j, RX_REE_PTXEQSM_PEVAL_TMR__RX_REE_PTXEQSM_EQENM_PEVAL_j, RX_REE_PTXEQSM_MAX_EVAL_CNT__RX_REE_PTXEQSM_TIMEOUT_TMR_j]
0x8200 RX_REE_PTXEQSM_EQENM_EVAL__RX_REE_PTXEQSM_CTRL_j reset 0x3BC70000 — REE PCIe TX equalization control state machine control register Offset = 8200h + (j * 400h); where j = 0h to 3h
  [31] RX_REE_PTXEQSM_EQENM_EVAL_15 rw — Reserved - spare
  [30] RX_REE_PTXEQSM_EQENM_EVAL_14 rw — Ignore 1010 controller : When set to 1'b1, this function is enabled when the PCIe TX equalization control state machine is controlling the REE.
  [29] RX_REE_PTXEQSM_EQENM_EVAL_13 rw — TX equalization evaluator : When set to 1'b1, this function is enabled when the PCIe TX equalization control state machine is controlling the REE.
  [28] RX_REE_PTXEQSM_EQENM_EVAL_12 rw — TX post cursor control : When set to 1'b1, this function is enabled when the PCIe TX equalization control state machine is controlling the REE.
  [27] RX_REE_PTXEQSM_EQENM_EVAL_11 rw — TX pre cursor control : When set to 1'b1, this function is enabled when the PCIe TX equalization control state machine is controlling the REE.
  [26] RX_REE_PTXEQSM_EQENM_EVAL_10 rw — Short channel correction : When set to 1'b1, this function is enabled when the TX equalization general control state machine is controlling the REE.
  [25] RX_REE_PTXEQSM_EQENM_EVAL_9 rw — RX attenuation : When set to 1'b1, this function is enabled when the PCIe TX equalization control state machine is controlling the REE.
  [24] RX_REE_PTXEQSM_EQENM_EVAL_8 rw — RX VGA gain : When set to 1'b1, this function is enabled when the PCIe TX equalization control state machine is controlling the REE.
  [23] RX_REE_PTXEQSM_EQENM_EVAL_7 rw — RX offset correction coefficient : When set to 1'b1, this function is enabled when the PCIe TX equalization control state machine is controlling the REE.
  [22] RX_REE_PTXEQSM_EQENM_EVAL_6 rw — RX peaking amp gain : When set to 1'b1, this function is enabled when the PCIe TX equalization control state machine is controlling the REE.
  [21] RX_REE_PTXEQSM_EQENM_EVAL_5 rw — RX low frequency equalizer adaptive control : When set to 1'b1, this function is enabled when the PCIe TX equalization control state machine is controlling the REE.
  [20] RX_REE_PTXEQSM_EQENM_EVAL_4 rw — Reserved - spare
  [19] RX_REE_PTXEQSM_EQENM_EVAL_3 rw — Reserved - spare
  [18] RX_REE_PTXEQSM_EQENM_EVAL_2 rw — RX tap3 : When set to 1'b1, this function is enabled when the PCIe TX equalization control state machine is controlling the REE.
  [17] RX_REE_PTXEQSM_EQENM_EVAL_1 rw — RX tap2 : When set to 1'b1, this function is enabled when the PCIe TX equalization control state machine is controlling the REE.
  [16] RX_REE_PTXEQSM_EQENM_EVAL_0 rw — RX tap1 : When set to 1'b1, this function is enabled when the PCIe TX equalization control state machine is controlling the REE.
  [15:0] RX_REE_PTXEQSM_CTRL_15_0 ro — Reserved
0x8204 RX_REE_PTXEQSM_PEVAL_TMR__RX_REE_PTXEQSM_EQENM_PEVAL_j rw — REE PCIe TX equalization control state machine equalization enable mask for PCIe post evaluation equalization register Offset = 8204h + (j * 400h); where j = 0h to 3h
  [31:16] RX_REE_PTXEQSM_PEVAL_TMR_15_0 — Run post evaluation equalization timer value : This specifies number of clock cycles the state machine will wait in the Post Evaluation Equalization state.
  [15] RX_REE_PTXEQSM_EQENM_PEVAL_15 — Reserved - spare
  [14] RX_REE_PTXEQSM_EQENM_PEVAL_14 — Ignore 1010 controller : When set to 1'b1, this function is enabled when the PCIe TX equalization control state machine is controlling the REE.
  [13] RX_REE_PTXEQSM_EQENM_PEVAL_13 — TX equalization evaluator : When set to 1'b1, this function is enabled when the PCIe TX equalization control state machine is controlling the REE.
  [12] RX_REE_PTXEQSM_EQENM_PEVAL_12 — TX post cursor control : When set to 1'b1, this function is enabled when the PCIe TX equalization control state machine is controlling the REE.
  [11] RX_REE_PTXEQSM_EQENM_PEVAL_11 — TX pre cursor control : When set to 1'b1, this function is enabled when the PCIe TX equalization control state machine is controlling the REE.
  [10] RX_REE_PTXEQSM_EQENM_PEVAL_10 — Short channel correction : When set to 1'b1, this function is enabled when the TX equalization general control state machine is controlling the REE.
  [9] RX_REE_PTXEQSM_EQENM_PEVAL_9 — RX attenuation : When set to 1'b1, this function is enabled when the PCIe TX equalization control state machine is controlling the REE.
  [8] RX_REE_PTXEQSM_EQENM_PEVAL_8 — RX VGA gain : When set to 1'b1, this function is enabled when the PCIe TX equalization control state machine is controlling the REE.
  [7] RX_REE_PTXEQSM_EQENM_PEVAL_7 — RX offset correction coefficient : When set to 1'b1, this function is enabled when the PCIe TX equalization control state machine is controlling the REE.
  [6] RX_REE_PTXEQSM_EQENM_PEVAL_6 — RX peaking amp gain : When set to 1'b1, this function is enabled when the PCIe TX equalization control state machine is controlling the REE.
  [5] RX_REE_PTXEQSM_EQENM_PEVAL_5 — RX low frequency equalizer adaptive control : When set to 1'b1, this function is enabled when the PCIe TX equalization control state machine is controlling the REE.
  [4] RX_REE_PTXEQSM_EQENM_PEVAL_4 — Reserved - spare
  [3] RX_REE_PTXEQSM_EQENM_PEVAL_3 — Reserved - spare
  [2] RX_REE_PTXEQSM_EQENM_PEVAL_2 — RX tap 3 : When set to 1'b1, this function is enabled when the PCIe TX equalization control state machine is controlling the REE.
  [1] RX_REE_PTXEQSM_EQENM_PEVAL_1 — RX tap 2 : When set to 1'b1, this function is enabled when the PCIe TX equalization control state machine is controlling the REE.
  [0] RX_REE_PTXEQSM_EQENM_PEVAL_0 — RX tap 1 : When set to 1'b1, this function is enabled when the PCIe TX equalization control state machine is controlling the REE.
0x8208 RX_REE_PTXEQSM_MAX_EVAL_CNT__RX_REE_PTXEQSM_TIMEOUT_TMR_j reset 0x3F30D4 — REE PCIe TX equalization control state machine time-out timer value register Offset = 8208h + (j * 400h); where j = 0h to 3h
  [31:22] RX_REE_PTXEQSM_MAX_EVAL_CNT_15_6 ro — Reserved
  [21:16] RX_REE_PTXEQSM_MAX_EVAL_CNT_5_0 rw — Incremental evaluation counter load value: This is the maximum number of incremental evaluations that will be performed plus one.
  [15:0] RX_REE_PTXEQSM_TIMEOUT_TMR_15_0 rw — Time-out timer load value: This specifies the number of clocks to run a PCIe evaluation before a time-out is indicated.
